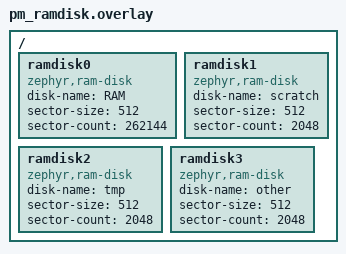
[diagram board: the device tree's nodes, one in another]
/ {
	/* FAT volume is /RAM: (ELM FatFs); mounted from main after mkfs. */

	ramdisk0 {
		compatible = "zephyr,ram-disk";
		disk-name = "RAM";
		sector-size = <512>;
		sector-count = <262144>; /* 128 MiB — python.wasm + stdlib + mods */
	};

	ramdisk1 {
		compatible = "zephyr,ram-disk";
		disk-name = "scratch";
		sector-size = <512>;
		sector-count = <2048>;
	};

	/* Product default guest /tmp (see app.c / zephyr_verify Stage B). */
	ramdisk2 {
		compatible = "zephyr,ram-disk";
		disk-name = "tmp";
		sector-size = <512>;
		sector-count = <2048>;
	};

	ramdisk3 {
		compatible = "zephyr,ram-disk";
		disk-name = "other";
		sector-size = <512>;
		sector-count = <2048>;
	};
};
